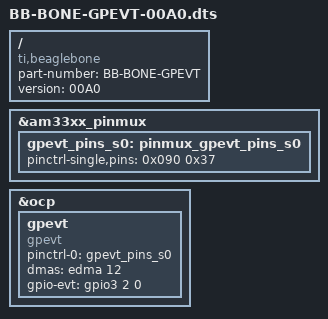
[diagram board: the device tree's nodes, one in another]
/*
 * This program is free software; you can redistribute it and/or modify
 * it under the terms of the GNU General Public License version 2 as
 * published by the Free Software Foundation.
 */
/dts-v1/;
/plugin/;

/ {
	compatible = "ti,beaglebone", "ti,beaglebone-black";

	/* identification */
	part-number = "BB-BONE-GPEVT";
	version = "00A0";

	fragment@0 {
		target = <&am33xx_pinmux>;
		__overlay__ {
			gpevt_pins_s0: pinmux_gpevt_pins_s0 {
				pinctrl-single,pins = <
					0x090 0x37	/* gpmc_advn_ale.gpio2_2, INPUT_PULLUP | MODE7 */
				>;
			};
		};
	};

	fragment@1 {
		target = <&ocp>;
		__overlay__ {
			gpevt {
				compatible = "gpevt";
				pinctrl-names = "default";
				pinctrl-0 = <&gpevt_pins_s0>;

				dmas = <&edma 12>;
				dma-names = "gpioevt";
				gpio-evt = <&gpio3 2 0>;
			};
		};
	};
};
